AUTOSAR XML (schema 4-2-2)
standard types defined: UINT8
package /ComponentType/ApplicationSwComponentType
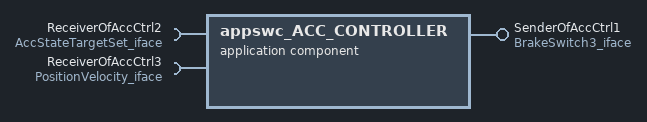
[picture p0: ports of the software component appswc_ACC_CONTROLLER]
  application sw component type appswc_ACC_CONTROLLER
    provide port SenderOfAccCtrl1: nonqueued-sender-com-spec{data-element=BrakeSwitch3_vdp, init-value=constant-reference=val_0}, provided-interface=BrakeSwitch3_iface
    require port ReceiverOfAccCtrl2: nonqueued-receiver-com-spec{data-element=AccStateTargetSet_vdp, init-value=constant-reference=val_0}, required-interface=AccStateTargetSet_iface
    require port ReceiverOfAccCtrl3: nonqueued-receiver-com-spec{data-element=PositionVelocity_vdp, init-value=constant-reference=val_0}, required-interface=PositionVelocity_iface
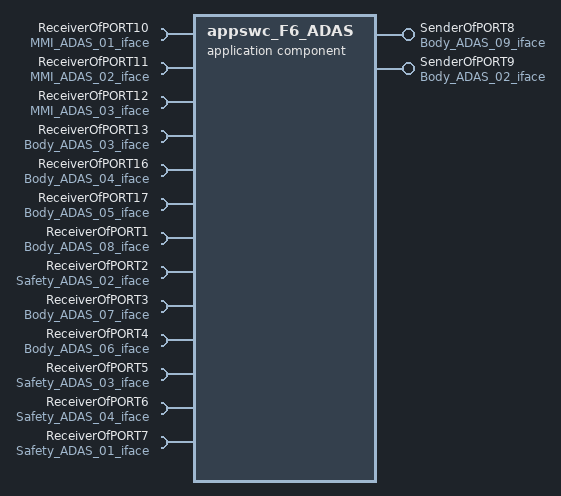
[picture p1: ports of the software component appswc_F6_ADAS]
  application sw component type appswc_F6_ADAS
    provide port SenderOfPORT8: nonqueued-sender-com-spec{data-element=Body_ADAS_09_vdp, init-value=constant-reference=val_0}, provided-interface=Body_ADAS_09_iface
    provide port SenderOfPORT9: nonqueued-sender-com-spec{data-element=Body_ADAS_02_vdp, init-value=constant-reference=val_0}, provided-interface=Body_ADAS_02_iface
    13 x require port:
      ReceiverOfPORT10: nonqueued-receiver-com-spec{data-element=MMI_ADAS_01_vdp, init-value=constant-reference=val_0}, required-interface=MMI_ADAS_01_iface
      ReceiverOfPORT11: nonqueued-receiver-com-spec{data-element=MMI_ADAS_02_vdp, init-value=constant-reference=val_0}, required-interface=MMI_ADAS_02_iface
      ReceiverOfPORT12: nonqueued-receiver-com-spec{data-element=MMI_ADAS_03_vdp, init-value=constant-reference=val_0}, required-interface=MMI_ADAS_03_iface
      ReceiverOfPORT13: nonqueued-receiver-com-spec{data-element=Body_ADAS_03_vdp, init-value=constant-reference=val_0}, required-interface=Body_ADAS_03_iface
      ReceiverOfPORT16: nonqueued-receiver-com-spec{data-element=Body_ADAS_04_vdp, init-value=constant-reference=val_0}, required-interface=Body_ADAS_04_iface
      ReceiverOfPORT17: nonqueued-receiver-com-spec{data-element=Body_ADAS_05_vdp, init-value=constant-reference=val_0}, required-interface=Body_ADAS_05_iface
      ReceiverOfPORT1: nonqueued-receiver-com-spec{data-element=Body_ADAS_08_vdp, init-value=constant-reference=val_0}, required-interface=Body_ADAS_08_iface
      ReceiverOfPORT2: nonqueued-receiver-com-spec{data-element=Safety_ADAS_02_vdp, init-value=constant-reference=val_0}, required-interface=Safety_ADAS_02_iface
      ReceiverOfPORT3: nonqueued-receiver-com-spec{data-element=Body_ADAS_07_vdp, init-value=constant-reference=val_0}, required-interface=Body_ADAS_07_iface
      ReceiverOfPORT4: nonqueued-receiver-com-spec{data-element=Body_ADAS_06_vdp, init-value=constant-reference=val_0}, required-interface=Body_ADAS_06_iface
      ReceiverOfPORT5: nonqueued-receiver-com-spec{data-element=Safety_ADAS_03_vdp, init-value=constant-reference=val_0}, required-interface=Safety_ADAS_03_iface
      ReceiverOfPORT6: nonqueued-receiver-com-spec{data-element=Safety_ADAS_04_vdp, init-value=constant-reference=val_0}, required-interface=Safety_ADAS_04_iface
      ReceiverOfPORT7: nonqueued-receiver-com-spec{data-element=Safety_ADAS_01_vdp, init-value=constant-reference=val_0}, required-interface=Safety_ADAS_01_iface
  application sw component type appswc_MaintainDistance
    provide port SenderOfMaintainDistance: nonqueued-sender-com-spec{data-element=MaintainDistance02_vdp, init-value=constant-reference=val_0}, provided-interface=MaintainDistance02_iface
package /DataType/ApplicationPrimitiveDataTypes
  6 x app type, all with compu-method=id_compu_meth_0001:
    dt_id_compu_meth_0001_UINT20: category=VALUE, base-type=UINT20
    dt_id_compu_meth_0001_UINT5: category=VALUE, base-type=UINT5
    dt_id_compu_meth_0001_UINT10: category=VALUE, base-type=UINT10
    dt_id_compu_meth_0001_UINT8: category=VALUE, base-type=UINT8
    dt_id_compu_meth_0001_UINT4: category=VALUE, base-type=UINT4
    dt_id_compu_meth_0001_BOOL: category=BOOLEAN
package /DataType/DataTypeSemantics
  compu method id_compu_meth_0001: texttable  # Identical conversion (Physical == Internal). Used by default if no other information
package /DataType/DataTypeSemantics/SwBaseTypes
  4 x base type, all with category=FIXED_LENGTH, base-type-encoding=NONE:
    UINT20: base-type-size=20, native-declaration=unsigned short
    UINT5: base-type-size=5
    UINT10: base-type-size=10, native-declaration=unsigned short
    UINT4: base-type-size=4
package /DataType/DataTypeMappingSet
  data type mapping set id_data_type_map_set_0002
    data-type-maps:
      application-data-type=dt_id_compu_meth_0001_BOOL, implementation-data-type=boolean
      application-data-type=dt_id_compu_meth_0001_UINT10, implementation-data-type=uint8
      application-data-type=dt_id_compu_meth_0001_UINT20, implementation-data-type=uint8
      application-data-type=dt_id_compu_meth_0001_UINT4, implementation-data-type=uint8
      application-data-type=dt_id_compu_meth_0001_UINT5, implementation-data-type=uint8
      application-data-type=dt_id_compu_meth_0001_UINT8, implementation-data-type=uint8
package /ECUExtractADAS/ComponentType
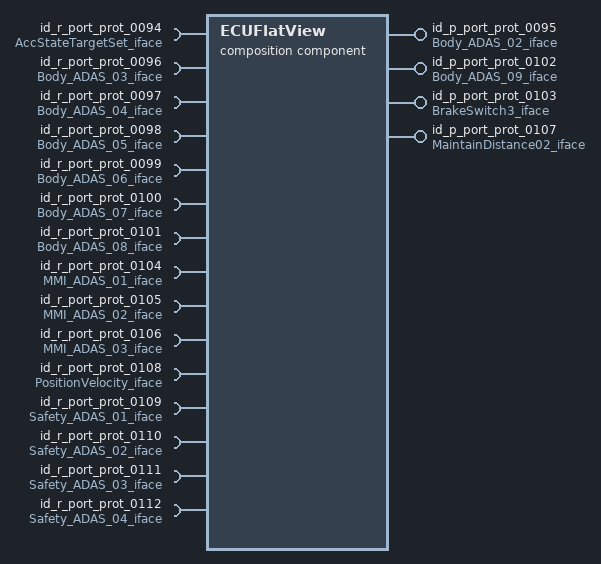
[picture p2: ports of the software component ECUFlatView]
  composition sw component type ECUFlatView
    4 x provide port:
      id_p_port_prot_0095: nonqueued-sender-com-spec{data-element=Body_ADAS_02_vdp, init-value=constant-reference=val_0}, provided-interface=Body_ADAS_02_iface
      id_p_port_prot_0102: nonqueued-sender-com-spec{data-element=Body_ADAS_09_vdp, init-value=constant-reference=val_0}, provided-interface=Body_ADAS_09_iface
      id_p_port_prot_0103: nonqueued-sender-com-spec{data-element=BrakeSwitch3_vdp, init-value=constant-reference=val_0}, provided-interface=BrakeSwitch3_iface
      id_p_port_prot_0107: nonqueued-sender-com-spec{data-element=MaintainDistance02_vdp, init-value=constant-reference=val_0}, provided-interface=MaintainDistance02_iface
    15 x require port:
      id_r_port_prot_0094: nonqueued-receiver-com-spec{data-element=AccStateTargetSet_vdp, init-value=constant-reference=val_0}, required-interface=AccStateTargetSet_iface
      id_r_port_prot_0096: nonqueued-receiver-com-spec{data-element=Body_ADAS_03_vdp, init-value=constant-reference=val_0}, required-interface=Body_ADAS_03_iface
      id_r_port_prot_0097: nonqueued-receiver-com-spec{data-element=Body_ADAS_04_vdp, init-value=constant-reference=val_0}, required-interface=Body_ADAS_04_iface
      id_r_port_prot_0098: nonqueued-receiver-com-spec{data-element=Body_ADAS_05_vdp, init-value=constant-reference=val_0}, required-interface=Body_ADAS_05_iface
      id_r_port_prot_0099: nonqueued-receiver-com-spec{data-element=Body_ADAS_06_vdp, init-value=constant-reference=val_0}, required-interface=Body_ADAS_06_iface
      id_r_port_prot_0100: nonqueued-receiver-com-spec{data-element=Body_ADAS_07_vdp, init-value=constant-reference=val_0}, required-interface=Body_ADAS_07_iface
      id_r_port_prot_0101: nonqueued-receiver-com-spec{data-element=Body_ADAS_08_vdp, init-value=constant-reference=val_0}, required-interface=Body_ADAS_08_iface
      id_r_port_prot_0104: nonqueued-receiver-com-spec{data-element=MMI_ADAS_01_vdp, init-value=constant-reference=val_0}, required-interface=MMI_ADAS_01_iface
      id_r_port_prot_0105: nonqueued-receiver-com-spec{data-element=MMI_ADAS_02_vdp, init-value=constant-reference=val_0}, required-interface=MMI_ADAS_02_iface
      id_r_port_prot_0106: nonqueued-receiver-com-spec{data-element=MMI_ADAS_03_vdp, init-value=constant-reference=val_0}, required-interface=MMI_ADAS_03_iface
      id_r_port_prot_0108: nonqueued-receiver-com-spec{data-element=PositionVelocity_vdp, init-value=constant-reference=val_0}, required-interface=PositionVelocity_iface
      id_r_port_prot_0109: nonqueued-receiver-com-spec{data-element=Safety_ADAS_01_vdp, init-value=constant-reference=val_0}, required-interface=Safety_ADAS_01_iface
      id_r_port_prot_0110: nonqueued-receiver-com-spec{data-element=Safety_ADAS_02_vdp, init-value=constant-reference=val_0}, required-interface=Safety_ADAS_02_iface
      id_r_port_prot_0111: nonqueued-receiver-com-spec{data-element=Safety_ADAS_03_vdp, init-value=constant-reference=val_0}, required-interface=Safety_ADAS_03_iface
      id_r_port_prot_0112: nonqueued-receiver-com-spec{data-element=Safety_ADAS_04_vdp, init-value=constant-reference=val_0}, required-interface=Safety_ADAS_04_iface
    component cswc_MaintainDistance: type=appswc_MaintainDistance
    component cswc_F6_ADAS: type=appswc_F6_ADAS
    component cswc_ACC_CONTROLLER: type=appswc_ACC_CONTROLLER
    delegate cswc_ACC_CONTROLLER.SenderOfAccCtrl1 <-> outer port id_p_port_prot_0103
    delegate cswc_F6_ADAS.SenderOfPORT8 <-> outer port id_p_port_prot_0102
    delegate cswc_F6_ADAS.SenderOfPORT9 <-> outer port id_p_port_prot_0095
    delegate cswc_MaintainDistance.SenderOfMaintainDistance <-> outer port id_p_port_prot_0107
    delegate cswc_ACC_CONTROLLER.ReceiverOfAccCtrl2 <-> outer port id_r_port_prot_0094
    delegate cswc_ACC_CONTROLLER.ReceiverOfAccCtrl3 <-> outer port id_r_port_prot_0108
    delegate cswc_F6_ADAS.ReceiverOfPORT10 <-> outer port id_r_port_prot_0104
    delegate cswc_F6_ADAS.ReceiverOfPORT11 <-> outer port id_r_port_prot_0105
    delegate cswc_F6_ADAS.ReceiverOfPORT12 <-> outer port id_r_port_prot_0106
    delegate cswc_F6_ADAS.ReceiverOfPORT13 <-> outer port id_r_port_prot_0096
    delegate cswc_F6_ADAS.ReceiverOfPORT16 <-> outer port id_r_port_prot_0097
    delegate cswc_F6_ADAS.ReceiverOfPORT17 <-> outer port id_r_port_prot_0098
    delegate cswc_F6_ADAS.ReceiverOfPORT1 <-> outer port id_r_port_prot_0101
    delegate cswc_F6_ADAS.ReceiverOfPORT2 <-> outer port id_r_port_prot_0110
    delegate cswc_F6_ADAS.ReceiverOfPORT3 <-> outer port id_r_port_prot_0100
    delegate cswc_F6_ADAS.ReceiverOfPORT4 <-> outer port id_r_port_prot_0099
    delegate cswc_F6_ADAS.ReceiverOfPORT5 <-> outer port id_r_port_prot_0111
    delegate cswc_F6_ADAS.ReceiverOfPORT6 <-> outer port id_r_port_prot_0112
    delegate cswc_F6_ADAS.ReceiverOfPORT7 <-> outer port id_r_port_prot_0109
package /ECUExtractADAS/VehicleProject
  system Physical_Platform_4Door:
    category=ECU_EXTRACT
    ecu-extract-version=0.0.0;20/11/05, ECU.Cfg.Ver: 0
    system-version=0.0.0; Export Project: Automotive EE platform Design: Physical Platform 4Door Version: RevC 2020-11-04 23-06-48 ARXML Link version 0.79A RemoveEmptyBusesAndECus : false AllowedCarrierTypes : Electrical, Optical, Wireless AllowedFunctionalTypes : Software Allowedimplementations : AllowedPlatformTypes : ECU AlwaysExportedVarianceSectionName : All ApplyFilterToObjectTypes : true BuildImplementationDataType : false ConsiderVariance : true ECUVariedWidePrefix : VAWI_ ECUWidePrefix : WID_ IncludeOTIData : true IncludeSoftSignals : false OutputOptionBasedVariance : true PreferSwComponentPrototypePerECU : false RecordDetailOfTimingData : false SplitSignalsWithMultipleSenders : false UseDefaultFilterTypes : true SimplerInterfacePattern : true
    system mapping id_syste_mapp_0875
      data-mappings:
        communication-direction=OUT, data-element=RootSwCompositionPrototype.id_p_port_prot_0095.Body_ADAS_02_vdp, system-signal=Body_ADAS_02
        communication-direction=OUT, data-element=RootSwCompositionPrototype.id_p_port_prot_0102.Body_ADAS_09_vdp, system-signal=Body_ADAS_09
        communication-direction=OUT, data-element=RootSwCompositionPrototype.id_p_port_prot_0103.BrakeSwitch3_vdp, system-signal=BrakeSwitch3
        communication-direction=OUT, data-element=RootSwCompositionPrototype.id_p_port_prot_0107.MaintainDistance02_vdp, system-signal=MaintainDistance
        communication-direction=IN, data-element=RootSwCompositionPrototype.id_r_port_prot_0094.AccStateTargetSet_vdp, system-signal=AccStateTargetSet
        communication-direction=IN, data-element=RootSwCompositionPrototype.id_r_port_prot_0096.Body_ADAS_03_vdp, system-signal=Body_ADAS_03
        communication-direction=IN, data-element=RootSwCompositionPrototype.id_r_port_prot_0097.Body_ADAS_04_vdp, system-signal=Body_ADAS_04
        communication-direction=IN, data-element=RootSwCompositionPrototype.id_r_port_prot_0098.Body_ADAS_05_vdp, system-signal=Body_ADAS_05
        communication-direction=IN, data-element=RootSwCompositionPrototype.id_r_port_prot_0099.Body_ADAS_06_vdp, system-signal=Body_ADAS_06
        communication-direction=IN, data-element=RootSwCompositionPrototype.id_r_port_prot_0100.Body_ADAS_07_vdp, system-signal=Body_ADAS_07
        communication-direction=IN, data-element=RootSwCompositionPrototype.id_r_port_prot_0101.Body_ADAS_08_vdp, system-signal=Body_ADAS_08
        communication-direction=IN, data-element=RootSwCompositionPrototype.id_r_port_prot_0104.MMI_ADAS_01_vdp, system-signal=MMI_ADAS_01
        communication-direction=IN, data-element=RootSwCompositionPrototype.id_r_port_prot_0105.MMI_ADAS_02_vdp, system-signal=MMI_ADAS_02
        communication-direction=IN, data-element=RootSwCompositionPrototype.id_r_port_prot_0106.MMI_ADAS_03_vdp, system-signal=MMI_ADAS_03
        communication-direction=IN, data-element=RootSwCompositionPrototype.id_r_port_prot_0108.PositionVelocity_vdp, system-signal=PositionVelocity
        communication-direction=IN, data-element=RootSwCompositionPrototype.id_r_port_prot_0109.Safety_ADAS_01_vdp, system-signal=Safety_ADAS_01
        communication-direction=IN, data-element=RootSwCompositionPrototype.id_r_port_prot_0110.Safety_ADAS_02_vdp, system-signal=Safety_ADAS_02
        communication-direction=IN, data-element=RootSwCompositionPrototype.id_r_port_prot_0111.Safety_ADAS_03_vdp, system-signal=Safety_ADAS_03
        communication-direction=IN, data-element=RootSwCompositionPrototype.id_r_port_prot_0112.Safety_ADAS_04_vdp, system-signal=Safety_ADAS_04
      sw-impl-mappings:
        swc to impl mapping SwcToImplMapping: component-implementation=Impl_appswc_ACC_CONTROLLER, component=RootSwCompositionPrototype.cswc_ACC_CONTROLLER
        swc to impl mapping SwcToImplMapping1: component-implementation=Impl_appswc_F6_ADAS, component=RootSwCompositionPrototype.cswc_F6_ADAS
        swc to impl mapping SwcToImplMapping2: component-implementation=Impl_appswc_MaintainDistance, component=RootSwCompositionPrototype.cswc_MaintainDistance
      sw-mappings:
        swc to ecu mapping id_swc_to_ecu_mapp_0876: ecu-instance=ADAS
          component:
            RootSwCompositionPrototype.cswc_MaintainDistance
            RootSwCompositionPrototype.cswc_F6_ADAS
            RootSwCompositionPrototype.cswc_ACC_CONTROLLER
    root-software-compositions:
      root sw composition prototype RootSwCompositionPrototype: software-composition=ECUFlatView
package /ECUSystem
  ecu instance ADAS: associated-com-i-pdu-group=[TxMPG_ctrl_ADAS_CAN_BODY, TxMPG_ctrl_ADAS_CAN_ACC, RxMPG_ctrl_ADAS_CAN_BODY, RxMPG_ctrl_ADAS_CAN_SAFETY, RxMPG_ctrl_ADAS_CAN_ACC], com-configuration-gw-time-base=0.005, com-configuration-rx-time-base=0.005, com-configuration-tx-time-base=0.005, sleep-mode-supported=false, wake-up-over-bus-supported=false
    can communication controller ctrl_ADAS_CAN_ACC
    can communication connector conn_ADAS_CAN_ACC: comm-controller=ctrl_ADAS_CAN_ACC
package /VehicleTopology
  can cluster CAN_ACC: baudrate=500000, protocol-name=CAN, protocol-version=CAN11
    can physical channel id_can_phys_chan_0825: comm-connectors=conn_ADAS_CAN_ACC
      frame ADAS_ACC_Frame: id 0x105, from ADAS, frame-length=8, can-addressing-mode=STANDARD, can-frame-tx-behavior=CAN-20
        pdu SignalIPdu6: length=8, transmission-mode-condition{data-filter=data-filter-type=ALWAYS, i-signal-in-i-pdu=isMaintainDistance_mtx}, transmission-mode-true-timing=cyclic-timing={time-offset=0.0, time-period=0.01}, unused-bit-pattern=0
          signal isBrakeSwitch3: start 7, 5 bit, big-endian, data-type-policy=NETWORK-REPRESENTATION-FROM-COM-SPEC, init-value=0, base-type=UINT5, compu-method=id_compu_meth_0001, transfer-property=PENDING
          signal isMaintainDistance: start 2, 5 bit, big-endian, data-type-policy=NETWORK-REPRESENTATION-FROM-COM-SPEC, init-value=0, base-type=UINT5, compu-method=id_compu_meth_0001, transfer-property=PENDING
      frame Radar_to_ADAS_Frame: id 0x201, to ADAS, frame-length=8, can-addressing-mode=STANDARD, can-frame-rx-behavior=CAN-20
        pdu SignalIPdu4: length=8, unused-bit-pattern=0
          signal isPositionVelocity: start 7, 5 bit, big-endian, data-type-policy=NETWORK-REPRESENTATION-FROM-COM-SPEC, init-value=0, base-type=UINT5, compu-method=id_compu_meth_0001, to ADAS
      frame PowertrainB_to_ADAS_Frame: id 0x202, to ADAS, frame-length=8, can-addressing-mode=STANDARD, can-frame-rx-behavior=CAN-20
        pdu SignalIPdu8: length=8, unused-bit-pattern=0
          signal isAccStateTargetSet: start 7, 5 bit, big-endian, data-type-policy=NETWORK-REPRESENTATION-FROM-COM-SPEC, init-value=0, base-type=UINT5, compu-method=id_compu_meth_0001, to ADAS
package /Interfaces
  19 x sender receiver interface:
    Body_ADAS_02_iface
      data Body_ADAS_02_vdp: type=dt_id_compu_meth_0001_UINT20
    Body_ADAS_09_iface
      data Body_ADAS_09_vdp: type=dt_id_compu_meth_0001_UINT20
    BrakeSwitch3_iface
      data BrakeSwitch3_vdp: type=dt_id_compu_meth_0001_UINT5
    MaintainDistance02_iface
      data MaintainDistance02_vdp: type=dt_id_compu_meth_0001_UINT5
    AccStateTargetSet_iface
      data AccStateTargetSet_vdp: type=dt_id_compu_meth_0001_UINT5
    Body_ADAS_03_iface
      data Body_ADAS_03_vdp: type=dt_id_compu_meth_0001_UINT20
    Body_ADAS_04_iface
      data Body_ADAS_04_vdp: type=dt_id_compu_meth_0001_UINT20
    Body_ADAS_05_iface
      data Body_ADAS_05_vdp: type=dt_id_compu_meth_0001_UINT20
    Body_ADAS_06_iface
      data Body_ADAS_06_vdp: type=dt_id_compu_meth_0001_UINT20
    Body_ADAS_07_iface
      data Body_ADAS_07_vdp: type=dt_id_compu_meth_0001_UINT20
    Body_ADAS_08_iface
      data Body_ADAS_08_vdp: type=dt_id_compu_meth_0001_UINT20
    MMI_ADAS_01_iface
      data MMI_ADAS_01_vdp: type=dt_id_compu_meth_0001_UINT10
    MMI_ADAS_02_iface
      data MMI_ADAS_02_vdp: type=dt_id_compu_meth_0001_UINT10
    MMI_ADAS_03_iface
      data MMI_ADAS_03_vdp: type=dt_id_compu_meth_0001_UINT10
    PositionVelocity_iface
      data PositionVelocity_vdp: type=dt_id_compu_meth_0001_UINT5
    Safety_ADAS_01_iface
      data Safety_ADAS_01_vdp: type=dt_id_compu_meth_0001_UINT8
    Safety_ADAS_02_iface
      data Safety_ADAS_02_vdp: type=dt_id_compu_meth_0001_UINT4
    Safety_ADAS_03_iface
      data Safety_ADAS_03_vdp: type=dt_id_compu_meth_0001_UINT4
    Safety_ADAS_04_iface
      data Safety_ADAS_04_vdp: type=dt_id_compu_meth_0001_UINT4
package /Constants
  constant specification val_0: value-spec=0
package /Communication/Frame
  5 x can frame, all with frame-length=8:
    ADAS_BODY_Frame
      pdu to frame mapping SignalIPdu7_map: packing-byte-order=little-endian, pdu=SignalIPdu7, start-position=0
    BodyRear_to_ADAS_Frame
      pdu to frame mapping SignalIPdu1_map: packing-byte-order=little-endian, pdu=SignalIPdu1, start-position=0
    Body_to_ADAS_Frame
      pdu to frame mapping SignalIPdu2_map: packing-byte-order=little-endian, pdu=SignalIPdu2, start-position=0
    MMI_to_ADAS_Frame
      pdu to frame mapping SignalIPdu3_map: packing-byte-order=little-endian, pdu=SignalIPdu3, start-position=0
    Safety_to_ADAS_Frame
      pdu to frame mapping SignalIPdu5_map: packing-byte-order=little-endian, pdu=SignalIPdu5, start-position=0
package /Communication/Pdu
  pdu SignalIPdu7: length=8, transmission-mode-condition{data-filter=data-filter-type=ALWAYS, i-signal-in-i-pdu=isBody_ADAS_02_mtx}, transmission-mode-true-timing=cyclic-timing={time-offset=0.0, time-period=0.01}, unused-bit-pattern=0
    signal isBody_ADAS_02: start 7, 20 bit, big-endian, data-type-policy=NETWORK-REPRESENTATION-FROM-COM-SPEC, init-value=0, base-type=UINT20, compu-method=id_compu_meth_0001, transfer-property=PENDING
    signal isBody_ADAS_09: start 19, 20 bit, big-endian, data-type-policy=NETWORK-REPRESENTATION-FROM-COM-SPEC, init-value=0, base-type=UINT20, compu-method=id_compu_meth_0001, transfer-property=PENDING
  pdu SignalIPdu1: length=8, unused-bit-pattern=0
    signal isBody_ADAS_03: start 7, 20 bit, big-endian, data-type-policy=NETWORK-REPRESENTATION-FROM-COM-SPEC, init-value=0, base-type=UINT20, compu-method=id_compu_meth_0001
    signal isBody_ADAS_04: start 19, 20 bit, big-endian, data-type-policy=NETWORK-REPRESENTATION-FROM-COM-SPEC, init-value=0, base-type=UINT20, compu-method=id_compu_meth_0001
    signal isBody_ADAS_05: start 47, 20 bit, big-endian, data-type-policy=NETWORK-REPRESENTATION-FROM-COM-SPEC, init-value=0, base-type=UINT20, compu-method=id_compu_meth_0001
  pdu SignalIPdu2: length=8, unused-bit-pattern=0
    signal isBody_ADAS_06: start 7, 20 bit, big-endian, data-type-policy=NETWORK-REPRESENTATION-FROM-COM-SPEC, init-value=0, base-type=UINT20, compu-method=id_compu_meth_0001
    signal isBody_ADAS_07: start 19, 20 bit, big-endian, data-type-policy=NETWORK-REPRESENTATION-FROM-COM-SPEC, init-value=0, base-type=UINT20, compu-method=id_compu_meth_0001
    signal isBody_ADAS_08: start 47, 20 bit, big-endian, data-type-policy=NETWORK-REPRESENTATION-FROM-COM-SPEC, init-value=0, base-type=UINT20, compu-method=id_compu_meth_0001
  pdu SignalIPdu3: length=8, unused-bit-pattern=0
    signal isMMI_ADAS_01: start 7, 10 bit, big-endian, data-type-policy=NETWORK-REPRESENTATION-FROM-COM-SPEC, init-value=0, base-type=UINT10, compu-method=id_compu_meth_0001
    signal isMMI_ADAS_02: start 13, 10 bit, big-endian, data-type-policy=NETWORK-REPRESENTATION-FROM-COM-SPEC, init-value=0, base-type=UINT10, compu-method=id_compu_meth_0001
    signal isMMI_ADAS_03: start 19, 10 bit, big-endian, data-type-policy=NETWORK-REPRESENTATION-FROM-COM-SPEC, init-value=0, base-type=UINT10, compu-method=id_compu_meth_0001
  pdu SignalIPdu5: length=8, unused-bit-pattern=0
    signal isSafety_ADAS_01: start 7, 8 bit, big-endian, data-type-policy=NETWORK-REPRESENTATION-FROM-COM-SPEC, init-value=0, base-type=UINT8, compu-method=id_compu_meth_0001
    signal isSafety_ADAS_02: start 15, 4 bit, big-endian, data-type-policy=NETWORK-REPRESENTATION-FROM-COM-SPEC, init-value=0, base-type=UINT4, compu-method=id_compu_meth_0001
    signal isSafety_ADAS_03: start 11, 4 bit, big-endian, data-type-policy=NETWORK-REPRESENTATION-FROM-COM-SPEC, init-value=0, base-type=UINT4, compu-method=id_compu_meth_0001
    signal isSafety_ADAS_04: start 23, 4 bit, big-endian, data-type-policy=NETWORK-REPRESENTATION-FROM-COM-SPEC, init-value=0, base-type=UINT4, compu-method=id_compu_meth_0001
package /Communication/ISignalPduGroup
  10 x i signal i pdu group:
    TxMPG_ctrl_ADAS_CAN_BODY: communication-direction=OUT, communication-mode=tx, contained-i-signal-i-pdu-group=TxSPG_ctrl_ADAS_CAN_BODY
    TxSPG_ctrl_ADAS_CAN_BODY: communication-direction=OUT, communication-mode=tx, i-signal-i-pdus=SignalIPdu7
    TxMPG_ctrl_ADAS_CAN_ACC: communication-direction=OUT, communication-mode=tx, contained-i-signal-i-pdu-group=TxSPG_ctrl_ADAS_CAN_ACC
    TxSPG_ctrl_ADAS_CAN_ACC: communication-direction=OUT, communication-mode=tx, i-signal-i-pdus=SignalIPdu6
    RxMPG_ctrl_ADAS_CAN_BODY: communication-direction=IN, communication-mode=rx, contained-i-signal-i-pdu-group=RxSPG_ctrl_ADAS_CAN_BODY
    RxSPG_ctrl_ADAS_CAN_BODY: communication-direction=IN, communication-mode=rx, i-signal-i-pdus=[SignalIPdu3, SignalIPdu2, SignalIPdu1]
    RxMPG_ctrl_ADAS_CAN_SAFETY: communication-direction=IN, communication-mode=rx, contained-i-signal-i-pdu-group=RxSPG_ctrl_ADAS_CAN_SAFETY
    RxSPG_ctrl_ADAS_CAN_SAFETY: communication-direction=IN, communication-mode=rx, i-signal-i-pdus=SignalIPdu5
    RxMPG_ctrl_ADAS_CAN_ACC: communication-direction=IN, communication-mode=rx, contained-i-signal-i-pdu-group=RxSPG_ctrl_ADAS_CAN_ACC
    RxSPG_ctrl_ADAS_CAN_ACC: communication-direction=IN, communication-mode=rx, i-signal-i-pdus=[SignalIPdu8, SignalIPdu4]
